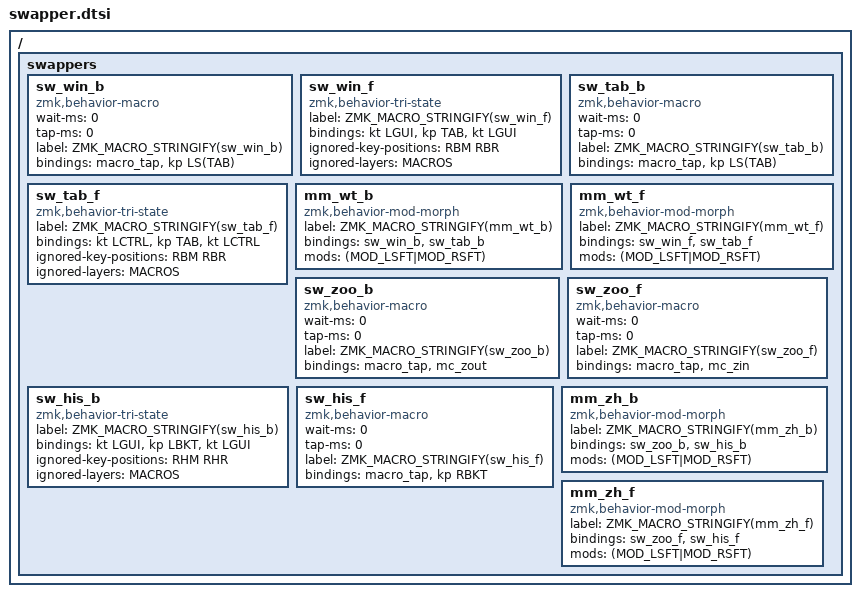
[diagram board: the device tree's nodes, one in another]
/*
*
* Copyright (c) 2022 Rafael Romão
* SPDX-License-Identifier: MIT
*
*/
/*                KEY POSITIONS

  ╭─────────────────────╮ ╭─────────────────────╮
  │ LTP LTR LTM LTI LTC │ │ RTC RTI RTM RTR RTP │
  │ LHP LHR LHM LHI LHC │ │ RHC RHI RHM RHR RHP │
  │ LBP LBR LBM LBI LBC │ │ RBC RBI RBM RBR RBP │
  ╰───────╮ L2  L1  L0  │ │ R0  R1  R2  ╭───────╯
          ╰─────────────╯ ╰─────────────╯ */


/ {
    swappers {
        sw_win_b: sw_win_b {
            wait-ms = <0>;
            tap-ms = <0>;
            label = ZMK_MACRO_STRINGIFY(sw_win_b);
            compatible = "zmk,behavior-macro";
            #binding-cells = <0>;
            bindings = <&macro_tap &kp LS(TAB)>;
        };
        sw_win_f: sw_win_f {
            compatible = "zmk,behavior-tri-state";
            label = ZMK_MACRO_STRINGIFY(sw_win_f);
            #binding-cells = <0>;
            bindings = <&kt LGUI>, <&kp TAB>, <&kt LGUI>;
            ignored-key-positions = <RBM RBR>;
            ignored-layers = <MACROS>;
        };
        sw_tab_b: sw_tab_b {
            wait-ms = <0>;
            tap-ms = <0>;
            label = ZMK_MACRO_STRINGIFY(sw_tab_b);
            compatible = "zmk,behavior-macro";
            #binding-cells = <0>;
            bindings = <&macro_tap &kp LS(TAB)>;
        };
        sw_tab_f: sw_tab_f {
            compatible = "zmk,behavior-tri-state";
            label = ZMK_MACRO_STRINGIFY(sw_tab_f);
            #binding-cells = <0>;
            bindings = <&kt LCTRL>, <&kp TAB>, <&kt LCTRL>;
            ignored-key-positions = <RBM RBR>;
            ignored-layers = <MACROS>;
        };
        mm_wt_b: mm_wt_b {
            compatible = "zmk,behavior-mod-morph";
            label = ZMK_MACRO_STRINGIFY(mm_wt_b);
            #binding-cells = <0>;
            bindings = <&sw_win_b>, <&sw_tab_b>;
            mods = <(MOD_LSFT|MOD_RSFT)>;
        };
        mm_wt_f: mm_wt_f {
            compatible = "zmk,behavior-mod-morph";
            label = ZMK_MACRO_STRINGIFY(mm_wt_f);
            #binding-cells = <0>;
            bindings = <&sw_win_f>, <&sw_tab_f>;
            mods = <(MOD_LSFT|MOD_RSFT)>;
        };

        sw_zoo_b: sw_zoo_b {
            wait-ms = <0>;
            tap-ms = <0>;
            label = ZMK_MACRO_STRINGIFY(sw_zoo_b);
            compatible = "zmk,behavior-macro";
            #binding-cells = <0>;
            bindings = <&macro_tap &mc_zout>;
        };
        sw_zoo_f: sw_zoo_f {
            wait-ms = <0>;
            tap-ms = <0>;
            label = ZMK_MACRO_STRINGIFY(sw_zoo_f);
            compatible = "zmk,behavior-macro";
            #binding-cells = <0>;
            bindings = <&macro_tap &mc_zin>;
        };
        sw_his_b: sw_his_b {
            compatible = "zmk,behavior-tri-state";
            label = ZMK_MACRO_STRINGIFY(sw_his_b);
            #binding-cells = <0>;
            bindings = <&kt LGUI>, <&kp LBKT>, <&kt LGUI>;
            ignored-key-positions = <RHM RHR>;
            ignored-layers = <MACROS>;
        };
        sw_his_f: sw_his_f {
            wait-ms = <0>;
            tap-ms = <0>;
            label = ZMK_MACRO_STRINGIFY(sw_his_f);
            compatible = "zmk,behavior-macro";
            #binding-cells = <0>;
            bindings = <&macro_tap &kp RBKT>;
        };
        mm_zh_b: mm_zh_b {
            compatible = "zmk,behavior-mod-morph";
            label = ZMK_MACRO_STRINGIFY(mm_zh_b);
            #binding-cells = <0>;
            bindings = <&sw_zoo_b>, <&sw_his_b>;
            mods = <(MOD_LSFT|MOD_RSFT)>;
        };
        mm_zh_f: mm_zh_f {
            compatible = "zmk,behavior-mod-morph";
            label = ZMK_MACRO_STRINGIFY(mm_zh_f);
            #binding-cells = <0>;
            bindings = <&sw_zoo_f>, <&sw_his_f>;
            mods = <(MOD_LSFT|MOD_RSFT)>;
        };
    };
};
